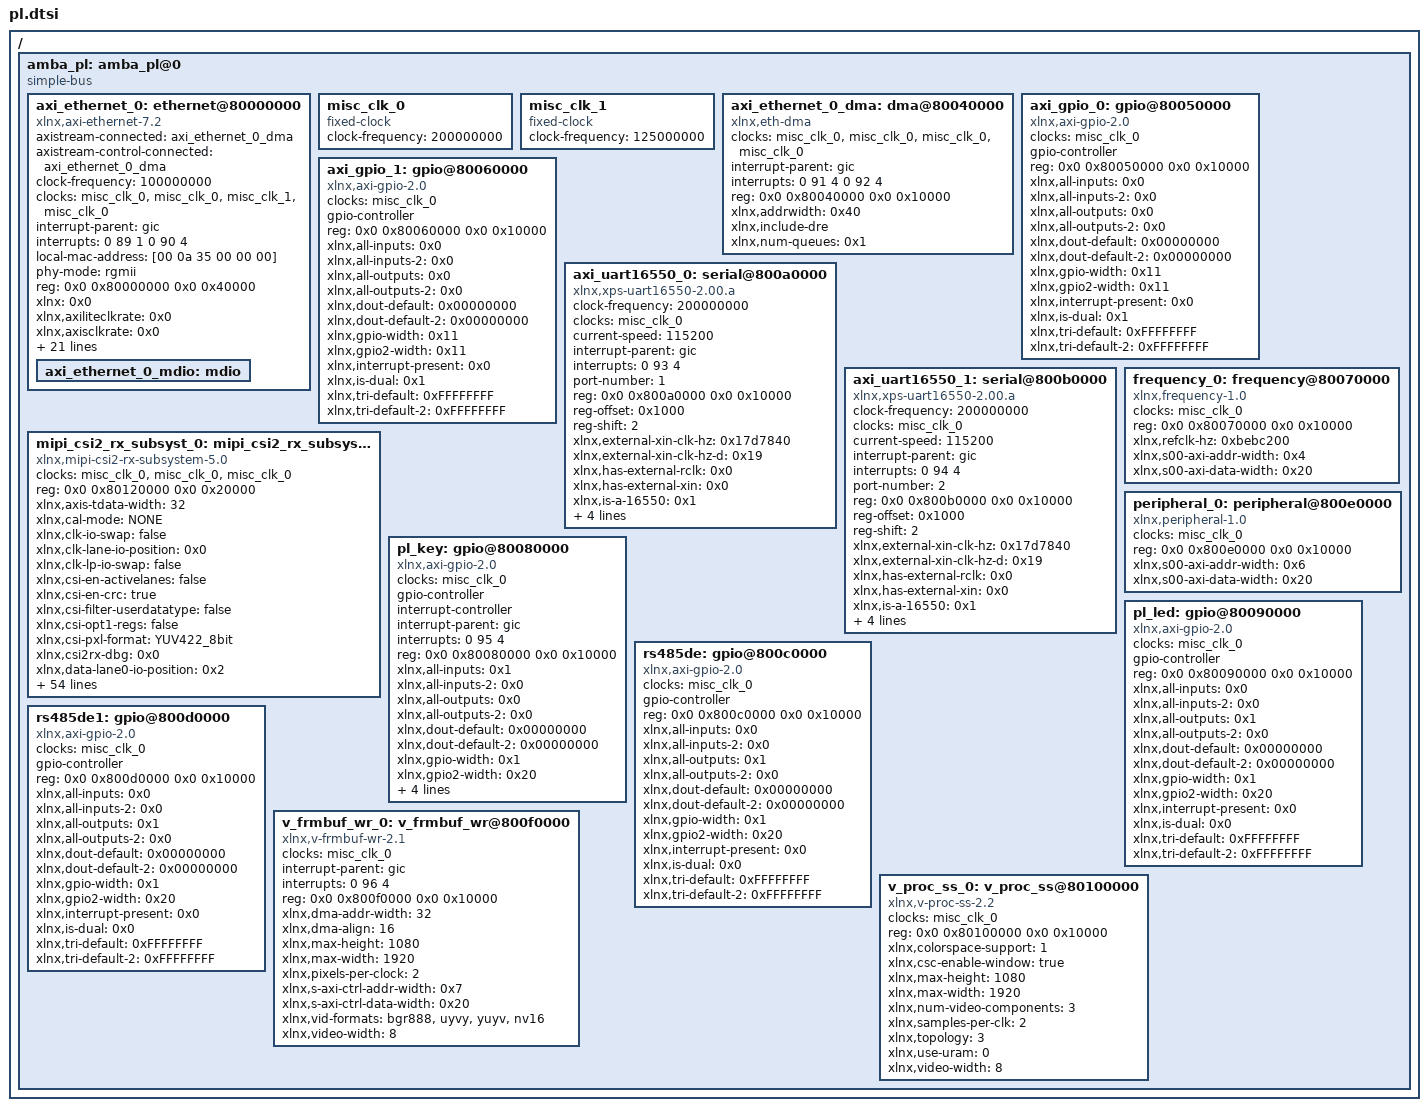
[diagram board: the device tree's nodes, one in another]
/*
 * CAUTION: This file is automatically generated by Xilinx.
 * Version:  
 * Today is: Tue Sep 15 01:32:22 2020
 */


/ {
	amba_pl: amba_pl@0 {
		#address-cells = <2>;
		#size-cells = <2>;
		compatible = "simple-bus";
		ranges ;
		axi_ethernet_0: ethernet@80000000 {
			axistream-connected = <&axi_ethernet_0_dma>;
			axistream-control-connected = <&axi_ethernet_0_dma>;
			clock-frequency = <100000000>;
			clock-names = "s_axi_lite_clk", "axis_clk", "gtx_clk", "ref_clk";
			clocks = <&misc_clk_0>, <&misc_clk_0>, <&misc_clk_1>, <&misc_clk_0>;
			compatible = "xlnx,axi-ethernet-7.2", "xlnx,axi-ethernet-1.00.a";
			device_type = "network";
			interrupt-names = "mac_irq", "interrupt";
			interrupt-parent = <&gic>;
			interrupts = <0 89 1 0 90 4>;
			local-mac-address = [00 0a 35 00 00 00];
			phy-mode = "rgmii";
			reg = <0x0 0x80000000 0x0 0x40000>;
			xlnx = <0x0>;
			xlnx,axiliteclkrate = <0x0>;
			xlnx,axisclkrate = <0x0>;
			xlnx,clockselection = <0x0>;
			xlnx,enableasyncsgmii = <0x0>;
			xlnx,gt-type = <0x0>;
			xlnx,gtinex = <0x0>;
			xlnx,gtlocation = <0x0>;
			xlnx,gtrefclksrc = <0x0>;
			xlnx,include-dre ;
			xlnx,instantiatebitslice0 = <0x0>;
			xlnx,phy-type = <0x3>;
			xlnx,phyaddr = <0x1>;
			xlnx,phyrst-board-interface-dummy-port = <0x0>;
			xlnx,rable = <0x0>;
			xlnx,rxcsum = <0x0>;
			xlnx,rxlane0-placement = <0x0>;
			xlnx,rxlane1-placement = <0x0>;
			xlnx,rxmem = <0x1000>;
			xlnx,rxnibblebitslice0used = <0x0>;
			xlnx,tx-in-upper-nibble = <0x1>;
			xlnx,txcsum = <0x0>;
			xlnx,txlane0-placement = <0x0>;
			xlnx,txlane1-placement = <0x0>;
			axi_ethernet_0_mdio: mdio {
				#address-cells = <1>;
				#size-cells = <0>;
			};
		};
		misc_clk_0: misc_clk_0 {
			#clock-cells = <0>;
			clock-frequency = <200000000>;
			compatible = "fixed-clock";
		};
		misc_clk_1: misc_clk_1 {
			#clock-cells = <0>;
			clock-frequency = <125000000>;
			compatible = "fixed-clock";
		};
		axi_ethernet_0_dma: dma@80040000 {
			#dma-cells = <1>;
			clock-names = "s_axi_lite_aclk", "m_axi_sg_aclk", "m_axi_mm2s_aclk", "m_axi_s2mm_aclk";
			clocks = <&misc_clk_0>, <&misc_clk_0>, <&misc_clk_0>, <&misc_clk_0>;
			compatible = "xlnx,eth-dma";
			interrupt-names = "mm2s_introut", "s2mm_introut";
			interrupt-parent = <&gic>;
			interrupts = <0 91 4 0 92 4>;
			reg = <0x0 0x80040000 0x0 0x10000>;
			xlnx,addrwidth = /bits/ 8 <0x40>;
			xlnx,include-dre ;
			xlnx,num-queues = /bits/ 16 <0x1>;
		};
		axi_gpio_0: gpio@80050000 {
			#gpio-cells = <3>;
			clock-names = "s_axi_aclk";
			clocks = <&misc_clk_0>;
			compatible = "xlnx,axi-gpio-2.0", "xlnx,xps-gpio-1.00.a";
			gpio-controller ;
			reg = <0x0 0x80050000 0x0 0x10000>;
			xlnx,all-inputs = <0x0>;
			xlnx,all-inputs-2 = <0x0>;
			xlnx,all-outputs = <0x0>;
			xlnx,all-outputs-2 = <0x0>;
			xlnx,dout-default = <0x00000000>;
			xlnx,dout-default-2 = <0x00000000>;
			xlnx,gpio-width = <0x11>;
			xlnx,gpio2-width = <0x11>;
			xlnx,interrupt-present = <0x0>;
			xlnx,is-dual = <0x1>;
			xlnx,tri-default = <0xFFFFFFFF>;
			xlnx,tri-default-2 = <0xFFFFFFFF>;
		};
		axi_gpio_1: gpio@80060000 {
			#gpio-cells = <3>;
			clock-names = "s_axi_aclk";
			clocks = <&misc_clk_0>;
			compatible = "xlnx,axi-gpio-2.0", "xlnx,xps-gpio-1.00.a";
			gpio-controller ;
			reg = <0x0 0x80060000 0x0 0x10000>;
			xlnx,all-inputs = <0x0>;
			xlnx,all-inputs-2 = <0x0>;
			xlnx,all-outputs = <0x0>;
			xlnx,all-outputs-2 = <0x0>;
			xlnx,dout-default = <0x00000000>;
			xlnx,dout-default-2 = <0x00000000>;
			xlnx,gpio-width = <0x11>;
			xlnx,gpio2-width = <0x11>;
			xlnx,interrupt-present = <0x0>;
			xlnx,is-dual = <0x1>;
			xlnx,tri-default = <0xFFFFFFFF>;
			xlnx,tri-default-2 = <0xFFFFFFFF>;
		};
		axi_uart16550_0: serial@800a0000 {
			clock-frequency = <200000000>;
			clock-names = "s_axi_aclk";
			clocks = <&misc_clk_0>;
			compatible = "xlnx,xps-uart16550-2.00.a", "ns16550a";
			current-speed = <115200>;
			device_type = "serial";
			interrupt-names = "ip2intc_irpt";
			interrupt-parent = <&gic>;
			interrupts = <0 93 4>;
			port-number = <1>;
			reg = <0x0 0x800a0000 0x0 0x10000>;
			reg-offset = <0x1000>;
			reg-shift = <2>;
			xlnx,external-xin-clk-hz = <0x17d7840>;
			xlnx,external-xin-clk-hz-d = <0x19>;
			xlnx,has-external-rclk = <0x0>;
			xlnx,has-external-xin = <0x0>;
			xlnx,is-a-16550 = <0x1>;
			xlnx,s-axi-aclk-freq-hz-d = "200.0";
			xlnx,sim-device = "VERSAL_AI_CORE_ES1";
			xlnx,use-modem-ports = <0x1>;
			xlnx,use-user-ports = <0x1>;
		};
		axi_uart16550_1: serial@800b0000 {
			clock-frequency = <200000000>;
			clock-names = "s_axi_aclk";
			clocks = <&misc_clk_0>;
			compatible = "xlnx,xps-uart16550-2.00.a", "ns16550a";
			current-speed = <115200>;
			device_type = "serial";
			interrupt-names = "ip2intc_irpt";
			interrupt-parent = <&gic>;
			interrupts = <0 94 4>;
			port-number = <2>;
			reg = <0x0 0x800b0000 0x0 0x10000>;
			reg-offset = <0x1000>;
			reg-shift = <2>;
			xlnx,external-xin-clk-hz = <0x17d7840>;
			xlnx,external-xin-clk-hz-d = <0x19>;
			xlnx,has-external-rclk = <0x0>;
			xlnx,has-external-xin = <0x0>;
			xlnx,is-a-16550 = <0x1>;
			xlnx,s-axi-aclk-freq-hz-d = "200.0";
			xlnx,sim-device = "VERSAL_AI_CORE_ES1";
			xlnx,use-modem-ports = <0x1>;
			xlnx,use-user-ports = <0x1>;
		};
		frequency_0: frequency@80070000 {
			clock-names = "s00_axi_aclk";
			clocks = <&misc_clk_0>;
			compatible = "xlnx,frequency-1.0";
			reg = <0x0 0x80070000 0x0 0x10000>;
			xlnx,refclk-hz = <0xbebc200>;
			xlnx,s00-axi-addr-width = <0x4>;
			xlnx,s00-axi-data-width = <0x20>;
		};
		mipi_csi2_rx_subsyst_0: mipi_csi2_rx_subsystem@80120000 {
			clock-names = "lite_aclk", "dphy_clk_200M", "video_aclk";
			clocks = <&misc_clk_0>, <&misc_clk_0>, <&misc_clk_0>;
			compatible = "xlnx,mipi-csi2-rx-subsystem-5.0";
			reg = <0x0 0x80120000 0x0 0x20000>;
			xlnx,axis-tdata-width = <32>;
			xlnx,cal-mode = "NONE";
			xlnx,clk-io-swap = "false";
			xlnx,clk-lane-io-position = <0x0>;
			xlnx,clk-lp-io-swap = "false";
			xlnx,csi-en-activelanes = "false";
			xlnx,csi-en-crc = "true";
			xlnx,csi-filter-userdatatype = "false";
			xlnx,csi-opt1-regs = "false";
			xlnx,csi-pxl-format = "YUV422_8bit";
			xlnx,csi2rx-dbg = <0x0>;
			xlnx,data-lane0-io-position = <0x2>;
			xlnx,data-lane1-io-position = <0x4>;
			xlnx,data-lane2-io-position = <0x6>;
			xlnx,data-lane3-io-position = <0x8>;
			xlnx,dl0-io-swap = "false";
			xlnx,dl0-lp-io-swap = "false";
			xlnx,dl1-io-swap = "false";
			xlnx,dl1-lp-io-swap = "false";
			xlnx,dl2-io-swap = "false";
			xlnx,dl2-lp-io-swap = "false";
			xlnx,dl3-io-swap = "false";
			xlnx,dl3-lp-io-swap = "false";
			xlnx,dphy-lanes = <0x2>;
			xlnx,dphy-mode = "SLAVE";
			xlnx,dphy-present ;
			xlnx,en-bg0-pin0 = "false";
			xlnx,en-bg0-pin6 = "false";
			xlnx,en-bg1-pin0 = "false";
			xlnx,en-bg1-pin6 = "false";
			xlnx,en-bg2-pin0 = "false";
			xlnx,en-bg2-pin6 = "false";
			xlnx,en-bg3-pin0 = "false";
			xlnx,en-bg3-pin6 = "false";
			xlnx,en-clk300m = "false";
			xlnx,en-cnts-byte-clk = "false";
			xlnx,en-csi-v2-0 = "false";
			xlnx,en-exdesigns = "false";
			xlnx,en-timeout-regs = "false";
			xlnx,en-vcx = "false";
			xlnx,esc-timeout = <0x6400>;
			xlnx,exdes-board = "ZCU102";
			xlnx,exdes-config = "MIPI_Video_Pipe_Camera_to_Display";
			xlnx,exdes-fmc = "LI-IMX274MIPI-FMC V1.0 Single Sensor";
			xlnx,fifo-rd-en-control = "true";
			xlnx,hs-line-rate = <0x3e8>;
			xlnx,hs-settle-ns = <0x91>;
			xlnx,hs-timeout = <0x10005>;
			xlnx,idly-group-name = "mipi_csi2rx_idly_group";
			xlnx,idly-tap = <0x1>;
			xlnx,init = <0x186a0>;
			xlnx,is-7series = "false";
			xlnx,is-versal = "false";
			xlnx,lprx-disable-extport = <0x0>;
			xlnx,max-lanes = <2>;
			xlnx,mipi-slv-int = <0x0>;
			xlnx,ooc-vid-clk = "6.666";
			xlnx,ppc = <2>;
			xlnx,rcve-alt-deskew-seq = "false";
			xlnx,rcve-deskew-seq = "false";
			xlnx,share-idlyctrl = "false";
			xlnx,stretch-line-rate = <0x9c4>;
			xlnx,vc = <4>;
			xlnx,vfb ;
		};
		peripheral_0: peripheral@800e0000 {
			clock-names = "s00_axi_aclk";
			clocks = <&misc_clk_0>;
			compatible = "xlnx,peripheral-1.0";
			reg = <0x0 0x800e0000 0x0 0x10000>;
			xlnx,s00-axi-addr-width = <0x6>;
			xlnx,s00-axi-data-width = <0x20>;
		};
		pl_key: gpio@80080000 {
			#gpio-cells = <3>;
			#interrupt-cells = <2>;
			clock-names = "s_axi_aclk";
			clocks = <&misc_clk_0>;
			compatible = "xlnx,axi-gpio-2.0", "xlnx,xps-gpio-1.00.a";
			gpio-controller ;
			interrupt-controller ;
			interrupt-names = "ip2intc_irpt";
			interrupt-parent = <&gic>;
			interrupts = <0 95 4>;
			reg = <0x0 0x80080000 0x0 0x10000>;
			xlnx,all-inputs = <0x1>;
			xlnx,all-inputs-2 = <0x0>;
			xlnx,all-outputs = <0x0>;
			xlnx,all-outputs-2 = <0x0>;
			xlnx,dout-default = <0x00000000>;
			xlnx,dout-default-2 = <0x00000000>;
			xlnx,gpio-width = <0x1>;
			xlnx,gpio2-width = <0x20>;
			xlnx,interrupt-present = <0x1>;
			xlnx,is-dual = <0x0>;
			xlnx,tri-default = <0xFFFFFFFF>;
			xlnx,tri-default-2 = <0xFFFFFFFF>;
		};
		pl_led: gpio@80090000 {
			#gpio-cells = <3>;
			clock-names = "s_axi_aclk";
			clocks = <&misc_clk_0>;
			compatible = "xlnx,axi-gpio-2.0", "xlnx,xps-gpio-1.00.a";
			gpio-controller ;
			reg = <0x0 0x80090000 0x0 0x10000>;
			xlnx,all-inputs = <0x0>;
			xlnx,all-inputs-2 = <0x0>;
			xlnx,all-outputs = <0x1>;
			xlnx,all-outputs-2 = <0x0>;
			xlnx,dout-default = <0x00000000>;
			xlnx,dout-default-2 = <0x00000000>;
			xlnx,gpio-width = <0x1>;
			xlnx,gpio2-width = <0x20>;
			xlnx,interrupt-present = <0x0>;
			xlnx,is-dual = <0x0>;
			xlnx,tri-default = <0xFFFFFFFF>;
			xlnx,tri-default-2 = <0xFFFFFFFF>;
		};
		rs485de: gpio@800c0000 {
			#gpio-cells = <3>;
			clock-names = "s_axi_aclk";
			clocks = <&misc_clk_0>;
			compatible = "xlnx,axi-gpio-2.0", "xlnx,xps-gpio-1.00.a";
			gpio-controller ;
			reg = <0x0 0x800c0000 0x0 0x10000>;
			xlnx,all-inputs = <0x0>;
			xlnx,all-inputs-2 = <0x0>;
			xlnx,all-outputs = <0x1>;
			xlnx,all-outputs-2 = <0x0>;
			xlnx,dout-default = <0x00000000>;
			xlnx,dout-default-2 = <0x00000000>;
			xlnx,gpio-width = <0x1>;
			xlnx,gpio2-width = <0x20>;
			xlnx,interrupt-present = <0x0>;
			xlnx,is-dual = <0x0>;
			xlnx,tri-default = <0xFFFFFFFF>;
			xlnx,tri-default-2 = <0xFFFFFFFF>;
		};
		rs485de1: gpio@800d0000 {
			#gpio-cells = <3>;
			clock-names = "s_axi_aclk";
			clocks = <&misc_clk_0>;
			compatible = "xlnx,axi-gpio-2.0", "xlnx,xps-gpio-1.00.a";
			gpio-controller ;
			reg = <0x0 0x800d0000 0x0 0x10000>;
			xlnx,all-inputs = <0x0>;
			xlnx,all-inputs-2 = <0x0>;
			xlnx,all-outputs = <0x1>;
			xlnx,all-outputs-2 = <0x0>;
			xlnx,dout-default = <0x00000000>;
			xlnx,dout-default-2 = <0x00000000>;
			xlnx,gpio-width = <0x1>;
			xlnx,gpio2-width = <0x20>;
			xlnx,interrupt-present = <0x0>;
			xlnx,is-dual = <0x0>;
			xlnx,tri-default = <0xFFFFFFFF>;
			xlnx,tri-default-2 = <0xFFFFFFFF>;
		};
		v_frmbuf_wr_0: v_frmbuf_wr@800f0000 {
			#dma-cells = <1>;
			clock-names = "ap_clk";
			clocks = <&misc_clk_0>;
			compatible = "xlnx,v-frmbuf-wr-2.1", "xlnx,axi-frmbuf-wr-v2.1";
			interrupt-names = "interrupt";
			interrupt-parent = <&gic>;
			interrupts = <0 96 4>;
			reg = <0x0 0x800f0000 0x0 0x10000>;
			xlnx,dma-addr-width = <32>;
			xlnx,dma-align = <16>;
			xlnx,max-height = <1080>;
			xlnx,max-width = <1920>;
			xlnx,pixels-per-clock = <2>;
			xlnx,s-axi-ctrl-addr-width = <0x7>;
			xlnx,s-axi-ctrl-data-width = <0x20>;
			xlnx,vid-formats = "bgr888", "uyvy", "yuyv", "nv16";
			xlnx,video-width = <8>;
		};
		v_proc_ss_0: v_proc_ss@80100000 {
			clock-names = "aclk";
			clocks = <&misc_clk_0>;
			compatible = "xlnx,v-proc-ss-2.2", "xlnx,vpss-csc", "xlnx,v-vpss-csc";
			reg = <0x0 0x80100000 0x0 0x10000>;
			xlnx,colorspace-support = <1>;
			xlnx,csc-enable-window = "true";
			xlnx,max-height = <1080>;
			xlnx,max-width = <1920>;
			xlnx,num-video-components = <3>;
			xlnx,samples-per-clk = <2>;
			xlnx,topology = <3>;
			xlnx,use-uram = <0>;
			xlnx,video-width = <8>;
		};
	};
};
